# STM32MP25_CM33 register map
File version: 1.3
CPU: CM33 r0p1, little endian, MPU, FPU, vendor SysTick, 8 interrupt priority bits
Registers are 32-bit, read-write, reset 0x0 unless marked. A register's access mark holds for its fields unless they carry their own. Offsets are from the block's base; [hi:lo] are bit positions; {n}, {i} and the like mark numbered series; 'fields as' and 'values as' point back to an identical list.

## ETHSW (part 2 of 2) — ETHSW register block
Base 0x4C000000
Same registers: ETHSW_S 0x5C000000
{0x220040+2i} ETHSW_FES2_FRAMESIZE{i}R 16-bit reset 0x7FF (i=0..7) — ETHSW FES port 2 frame size {i} configuration register
  [10:0] FRAMESIZE — Max frame size
{0x2200E0+2i} ETHSW_FES2_FL_Q{i}_MINR 16-bit (i=0..7) — ETHSW FES port 2 minimum fill level queue {i} register
  [4:0] FL_QY_MIN — Minimum fill level for queue y
{0x2200F0+2i} ETHSW_FES2_FL_Q{i}_MAXR 16-bit (i=0..7) — ETHSW FES port 2 maximum fill level queue {i} register
  [4:0] FL_QY_MAX — Maximum fill level for queue y
0x800000 ETHSW_FES_IPC_IDR ro reset 0x4000 — ETHSW FES IP core identification register
  [31:8] DEV_ID — Device ID
    64=FES
0x800004 ETHSW_FES_CFG_IDR 16-bit ro reset 0x1 — ETHSW FES configuration ID register
  [15:0] CFG_ID — Configuration ID
0x800006 ETHSW_FES_REV_ID0R 16-bit ro reset 0xF2AF — ETHSW FES revision ID register 0
  [15:0] REV_ID0 — Configuration revision ID 0
0x800008 ETHSW_FES_REV_ID1R 16-bit ro reset 0x71CA — ETHSW FES revision ID register 1
  [15:0] REV_ID1 — Body revision ID, bit (15:0)
0x80000A ETHSW_FES_REV_ID2R 16-bit ro reset 0x57D — ETHSW FES revision ID register 2
  [15:0] REV_ID2 — Body revision ID, bit (31:16)
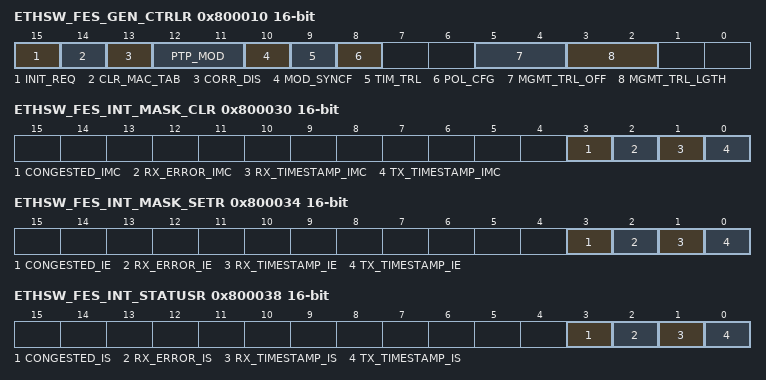
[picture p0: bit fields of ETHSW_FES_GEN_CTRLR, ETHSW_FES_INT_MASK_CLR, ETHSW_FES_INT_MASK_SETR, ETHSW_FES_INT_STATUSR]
0x800010 ETHSW_FES_GEN_CTRLR 16-bit — ETHSW FES general control register
  [15] INIT_REQ — Init Request
    0=Initialization release; 1=Initialization request
  [14] CLR_MAC_TAB — Clear Dynamic MAC address table
  [13] CORR_DIS — Correction Disable
    0=correctionFields of Store-and-forward PTPv2 event messages (Sync, Delay_Req, Pdelay_Req and Pdelay_Resp) are modified to include the time the frame spent inside the switch and for Sync frames optionally the link delay of the ingress port; 1=correctionFields of PTPv2 event messages are not modified by FES
  [12:11] PTP_MOD — PTP Mode
    0=PTP over UDP/IPv4; 2=PTP over Ethernet
  [10] MOD_SYNCF — Modify Sync frames
    0=Disabled; 1=Enabled
  [9] TIM_TRL — Time trailer
    0=Disabled; 1=Enabled
  [8] POL_CFG — Policer configuration
    0=Policing based on IPO; 1=Policing based on Static MAC Address Table
  [5:4] MGMT_TRL_OFF — Management Trailer Offset
    0=normal operation; 1=8-bit offset
  [3:2] MGMT_TRL_LGTH — Management Trailer Length
    0=8 bits; 1=16 bits
0x800012 ETHSW_FES_MT_CLEAR_MSKR 16-bit reset 0x7 — ETHSW FES dynamic MAC table clear mask register
  [2:0] MAC_TAB_CLRM — MAC Table Clear Mask
    0=Entries registered to this port are not cleared; 1=Entries registered to this port are cleared
0x800014 ETHSW_FES_MT_CLEAR_FIDR 16-bit — ETHSW FES dynamic MAC table clear FID register
  [5:0] FID — Filtering Identifier (FID)
0x800020 ETHSW_FES_ADDRESS_AGING_CFGR 16-bit reset 0x12 — ETHSW FES address aging configuration register
  [6:0] LIFE_TIME — Address Lifetime
    0=16s; 1=32s
0x800022 ETHSW_FES_AGING_BASE_TIMELR 16-bit reset 0xA11F — ETHSW FES aging base time low register
  [15:0] BASE_TIMEL — Aging base time value bits (15:0)
0x800024 ETHSW_FES_AGING_BASE_TIMEHR 16-bit reset 0x7 — ETHSW FES aging base time high register
  [7:0] BASE_TIMEH — Aging base time value bits (23:16)
0x800030 ETHSW_FES_INT_MASK_CLR 16-bit — ETHSW FES interrupt mask clear register
  [3] CONGESTED_IMC — Congested interrupt mask clear
  [2] RX_ERROR_IMC — RX error interrupt mask clear
  [1] RX_TIMESTAMP_IMC — RX timestamp interrupt mask clear
  [0] TX_TIMESTAMP_IMC — TX timestamp interrupt mask clear
0x800034 ETHSW_FES_INT_MASK_SETR 16-bit — ETHSW FES interrupt mask set register
  [3] CONGESTED_IE — Congested interrupt enable mask
  [2] RX_ERROR_IE — RX error interrupt enable mask
  [1] RX_TIMESTAMP_IE — RX timestamp interrupt enable mask
  [0] TX_TIMESTAMP_IE — TX timestamp interrupt enable mask
0x800038 ETHSW_FES_INT_STATUSR 16-bit — ETHSW FES interrupt status register
  [3] CONGESTED_IS — Congested interrupt status
  [2] RX_ERROR_IS — RX error interrupt status
  [1] RX_TIMESTAMP_IS — RX timestamp interrupt status
  [0] TX_TIMESTAMP_IS — TX timestamp interrupt status
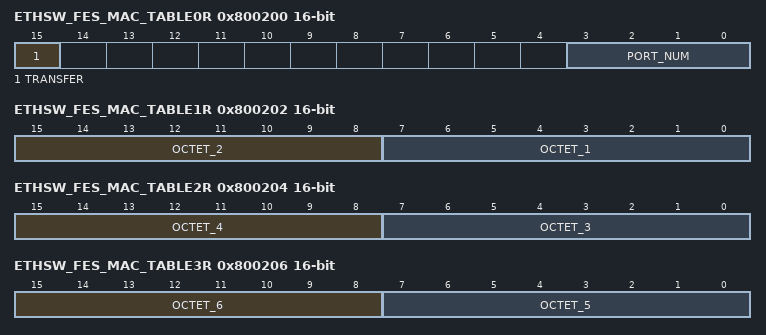
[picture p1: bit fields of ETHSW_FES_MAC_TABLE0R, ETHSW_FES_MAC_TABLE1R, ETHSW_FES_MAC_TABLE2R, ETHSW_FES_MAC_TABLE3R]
0x800200 ETHSW_FES_MAC_TABLE0R 16-bit — ETHSW FES dynamic MAC table read 0 register
  [15] TRANSFER
  [3:0] PORT_NUM ro — Port number
0x800202 ETHSW_FES_MAC_TABLE1R 16-bit ro — ETHSW FES dynamic MAC table read 1 register
  [15:8] OCTET_2 — Dynamic MAC Address Table Read: 2less thansup>ndless than/sup> octet
  [7:0] OCTET_1 — Dynamic MAC Address Table Read: 1less thansup>stless than/sup> octet
0x800204 ETHSW_FES_MAC_TABLE2R 16-bit ro — ETHSW FES dynamic MAC table read 2 register
  [15:8] OCTET_4 — Dynamic MAC Address Table Read: 4less thansup>thless than/sup> octet
  [7:0] OCTET_3 — Dynamic MAC Address Table Read: 3less thansup>rdless than/sup> octet
0x800206 ETHSW_FES_MAC_TABLE3R 16-bit ro — ETHSW FES dynamic MAC table read 3 register
  [15:8] OCTET_6 — Dynamic MAC Address Table Read: 6less thansup>thless than/sup> octet
  [7:0] OCTET_5 — Dynamic MAC Address Table Read: 5less thansup>thless than/sup> octet
0x800208 ETHSW_FES_MAC_TABLE4R 16-bit ro — ETHSW FES dynamic MAC table read 4 register
  [5:0] FID
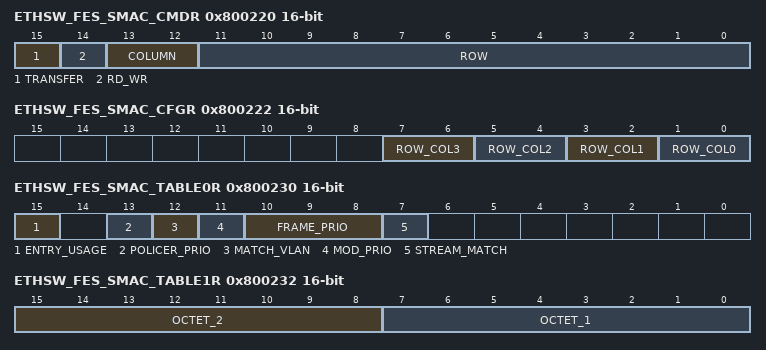
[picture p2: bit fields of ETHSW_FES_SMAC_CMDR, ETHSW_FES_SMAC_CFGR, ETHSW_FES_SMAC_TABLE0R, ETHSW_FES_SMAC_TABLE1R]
0x800220 ETHSW_FES_SMAC_CMDR 16-bit — ETHSW FES static MAC address table R/W command register
  [15] TRANSFER
  [14] RD_WR — Read / write
    0=Read values from Static MAC Table Entry to registers; 1=Write values from registers into Static MAC Table Entry
  [13:12] COLUMN
  [11:0] ROW
0x800222 ETHSW_FES_SMAC_CFGR 16-bit — ETHSW FES static MAC address table configuration register
  [7:6] ROW_COL3 — Row selection setting for column 3
  [5:4] ROW_COL2 — Row selection setting for column 2
  [3:2] ROW_COL1 — Row selection setting for column1
  [1:0] ROW_COL0 — Row selection setting for column 0
    0=XOR with VLAN disabled; 1=XOR with VLAN enabled
0x800230 ETHSW_FES_SMAC_TABLE0R 16-bit — ETHSW FES static MAC address table read/write 0 register
  [15] ENTRY_USAGE
    0=The entry is not used for altering Forward PortMask, Priority and Policer number for frames; 1=The entry is used for altering Forward PortMask of frames
  [13] POLICER_PRIO — Policer priority
    0=Normal Policer priority; 1=Low Policer priority, frames with lower policer priority use only the upper half of the token buckets
  [12] MATCH_VLAN
    0=Do not care about the VLAN of the frame; 1=Check that the value in VLAN field (ETHSW FES static MAC address table read/write 7 register (ETHSW_FES_SMAC_TABLE7R)) matches to VLAN of the frame
  [11] MOD_PRIO — Modify Priority
    0=Do not change frame priority; 1=Change the priority of the frame to the value in bits (10:8) of this register
  [10:8] FRAME_PRIO — Frame Priority
  [7] STREAM_MATCH — Stream_number source/destination match
    0=stream_number in this entry is used only for frames whose source address matches to the address in registers from ETHSW FES static MAC address table read/write 1 register (ETHSW_FES_SMAC_TABLE1R) to ETHSW FES static MAC address table read/write 3 register (ETHSW_FES_SMAC_TABLE3R); 1=stream_number in this entry is used only for frames whose destination address matches to the address in registers from ETHSW FES static MAC address table read/write 1 register (ETHSW_FES_SMAC_TABLE1R) to ETHSW FES static MAC address table read/write 3 register (ETHSW_FES_SMAC_TABLE3R)
0x800232 ETHSW_FES_SMAC_TABLE1R 16-bit — ETHSW FES static MAC address table read/write 1 register
  [15:8] OCTET_2 — Static MAC Address Table Read: 2less thansup>ndless than/sup> octet
  [7:0] OCTET_1 — Static MAC Address Table Read: 1less thansup>stless than/sup> octet
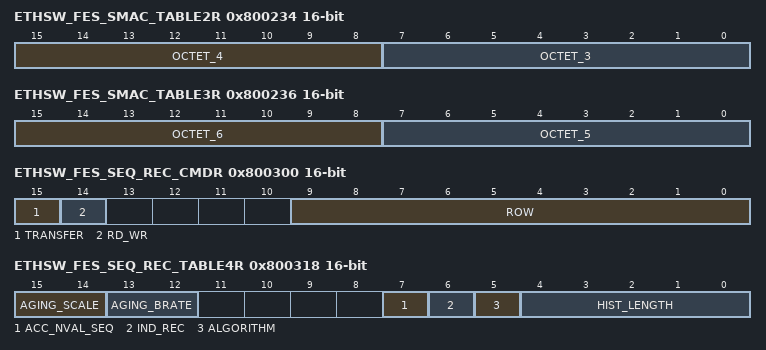
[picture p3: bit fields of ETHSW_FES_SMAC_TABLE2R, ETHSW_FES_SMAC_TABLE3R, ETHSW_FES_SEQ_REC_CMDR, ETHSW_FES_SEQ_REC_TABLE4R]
0x800234 ETHSW_FES_SMAC_TABLE2R 16-bit — ETHSW FES static MAC address table read/write 2 register
  [15:8] OCTET_4 — Static MAC Address Table Read: 4less thansup>thless than/sup> octet
  [7:0] OCTET_3 — Static MAC Address Table Read: 3less thansup>rdless than/sup> octet
0x800236 ETHSW_FES_SMAC_TABLE3R 16-bit — ETHSW FES static MAC address table read/write 3 register
  [15:8] OCTET_6 — Static MAC Address Table Read: 6less thansup>thless than/sup> octet
  [7:0] OCTET_5 — Static MAC Address Table Read: 5less thansup>thless than/sup> octet
0x800238 ETHSW_FES_SMAC_TABLE4R 16-bit — ETHSW FES static MAC address table read/write 4 register
  [2:0] FWD_PORT_MSK — Forward Port Mask
    0=Do not forward frames whose destination address matches to the port; 1=Forward frames whose destination address matches to the port
0x80023A ETHSW_FES_SMAC_TABLE5R 16-bit — ETHSW FES static MAC address table read/write 5 register
  [2:0] POLICER_PORTS — Policed Ports
    0=Keep the default policer for this input port; 1=Change policer mapping (to Policer Number in ETHSW FES static MAC address table read/write 6 register (ETHSW_FES_SMAC_TABLE6R)) for this input port
0x80023C ETHSW_FES_SMAC_TABLE6R 16-bit — ETHSW FES static MAC address table read/write 6 register
  [11:0] POLICER_NUM — Policer Number
0x80023E ETHSW_FES_SMAC_TABLE7R 16-bit — ETHSW FES static MAC address table read/write 7 register
  [11:0] VLAN
0x800300 ETHSW_FES_SEQ_REC_CMDR 16-bit — ETHSW FES sequence recovery table R/W command register
  [15] TRANSFER
  [14] RD_WR — Read / write
    0=Read value from Sequence Recovery Table row to ETHSW FES sequence recovery table read/write 4 register (ETHSW_FES_SEQ_REC_TABLE4R); 1=Write value from ETHSW FES sequence recovery table read/write 4 register (ETHSW_FES_SEQ_REC_TABLE4R) to Sequence Generation Table row
  [9:0] ROW
0x800318 ETHSW_FES_SEQ_REC_TABLE4R 16-bit — ETHSW FES sequence recovery table read/write 4 register
  [15:14] AGING_SCALE — Aging rate scale
  [13:12] AGING_BRATE — Aging basic rate
  [7] ACC_NVAL_SEQ — Accept non valid sequence
    0=Drop frames that have no valid sequence number; 1=Accept frames that have no valid sequence number
  [6] IND_REC — Individual recovery
    0=Frames discarded as duplicates do not cause the aging timer to be reset; 1=Frames discarded as duplicates cause the aging timer to be reset
  [5] ALGORITHM
    0=Vector Recovery Algorithm; 1=Match Recovery Algorithm
  [4:0] HIST_LENGTH — History Length - 1
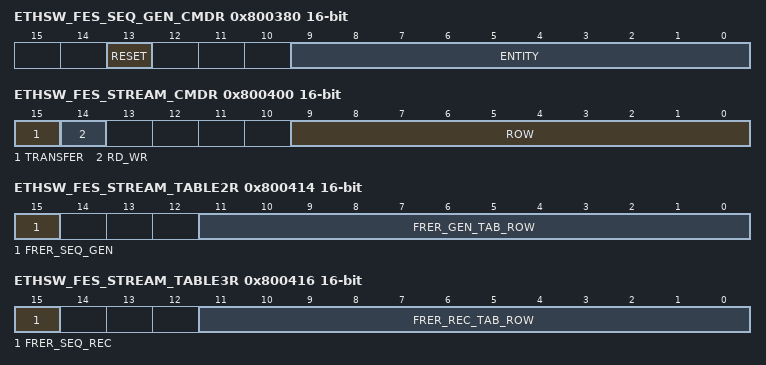
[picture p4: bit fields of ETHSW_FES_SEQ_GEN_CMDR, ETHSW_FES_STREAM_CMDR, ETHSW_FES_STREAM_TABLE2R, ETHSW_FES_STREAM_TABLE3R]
0x800380 ETHSW_FES_SEQ_GEN_CMDR 16-bit — ETHSW FES sequence generation command register
  [13] RESET
    0=Do nothing; 1=Reset sequence number
  [9:0] ENTITY
0x800400 ETHSW_FES_STREAM_CMDR 16-bit — ETHSW FES stream table R/W command register
  [15] TRANSFER
  [14] RD_WR — Read / write
    0=Read values from Stream Table row to registers from ETHSW FES stream table read/write 0 register (ETHSW_FES_STREAM_TABLE0R) to ETHSW FES stream table read/write 3 register (ETHSW_FES_STREAM_TABLE3R); 1=Write values from registers ETHSW FES stream table read/write 0 register (ETHSW_FES_STREAM_TABLE0R) to ETHSW FES stream table read/write 3 register (ETHSW_FES_STREAM_TABLE3R) into Stream Table row
  [9:0] ROW
0x800410 ETHSW_FES_STREAM_TABLE0R 16-bit — ETHSW FES stream table read/write 0 register
  [2:0] RMV_RTAG — Remove R-TAGging input port vector
    0=Keep R-TAGging; 1=Remove R-TAGging
0x800412 ETHSW_FES_STREAM_TABLE1R 16-bit — ETHSW FES stream table read/write 1 register
  [2:0] ADD_RTAG — Add R-TAGging output port vector
    0=Keep R-TAGging; 1=Add R-TAGging
0x800414 ETHSW_FES_STREAM_TABLE2R 16-bit — ETHSW FES stream table read/write 2 register
  [15] FRER_SEQ_GEN — FRER sequence generation enable
    0=Sequence generation functionality disabled for the stream; 1=Sequence generation functionality enabled, bits (11:0) of this register provide a pointer to Sequence generation table row (Sequence generation function entity)
  [11:0] FRER_GEN_TAB_ROW — FRER sequence generation table row
0x800416 ETHSW_FES_STREAM_TABLE3R 16-bit — ETHSW FES stream table read/write 3 register
  [15] FRER_SEQ_REC — FRER sequence recovery enable
    0=Sequence recovery functionality disabled for the stream; 1=Sequence recovery functionality enabled, bits (11:0) of this register provide a pointer to Sequence recovery table row (Sequence recovery function entity)
  [11:0] FRER_REC_TAB_ROW — FRER sequence recovery table row
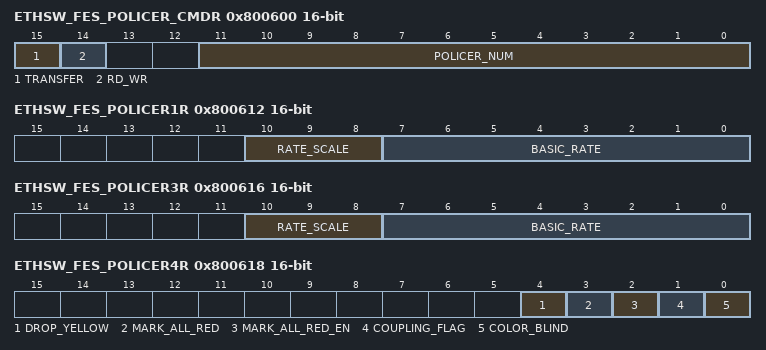
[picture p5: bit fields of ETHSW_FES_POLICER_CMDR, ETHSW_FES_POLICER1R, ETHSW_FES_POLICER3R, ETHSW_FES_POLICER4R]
0x800600 ETHSW_FES_POLICER_CMDR 16-bit — ETHSW FES policer read/write command register
  [15] TRANSFER
  [14] RD_WR — Read / write
    0=Read values from policer internal registers to registers ETHSW FES policer read/write 0 register (ETHSW_FES_POLICER0R) to ETHSW FES policer read/write 4 register (ETHSW_FES_POLICER4R); 1=Write values from registers ETHSW FES policer read/write 0 register (ETHSW_FES_POLICER0R) to ETHSW FES policer read/write 4 register (ETHSW_FES_POLICER4R) to policer internal registers
  [11:0] POLICER_NUM — Policer Number
0x800610 ETHSW_FES_POLICER0R 16-bit — ETHSW FES policer read/write 0 register
  [15:0] LIMIT
0x800612 ETHSW_FES_POLICER1R 16-bit — ETHSW FES policer read/write 1 register
  [10:8] RATE_SCALE — Rate Scale of Meter 0 (the meter for green)
  [7:0] BASIC_RATE — Basic Rate of Meter 0 (the meter for green)
0x800614 ETHSW_FES_POLICER2R 16-bit — ETHSW FES policer read/write 2 register
  [15:0] LIMIT
0x800616 ETHSW_FES_POLICER3R 16-bit — ETHSW FES policer read/write 3 register
  [10:8] RATE_SCALE — Rate Scale of Meter 1 (the meter for yellow / red)
  [7:0] BASIC_RATE — Basic Rate of Meter 1 (the meter for yellow / red)
0x800618 ETHSW_FES_POLICER4R 16-bit — ETHSW FES policer read/write 4 register
  [4] DROP_YELLOW — Drop on Yellow
    0=Disabled; 1=Enabled
  [3] MARK_ALL_RED — Mark all Frames Red
  [2] MARK_ALL_RED_EN — Mark all Frames Red Enable
    0=Disabled; 1=Enabled
  [1] COUPLING_FLAG
    0=No coupling between Meter 0 and Meter 1; 1=Tokens overflowing from the bucket of Meter 0 (green) are given to Meter 1 (yellow / red)
  [0] COLOR_BLIND
    0=Color Aware; 1=Color Blind
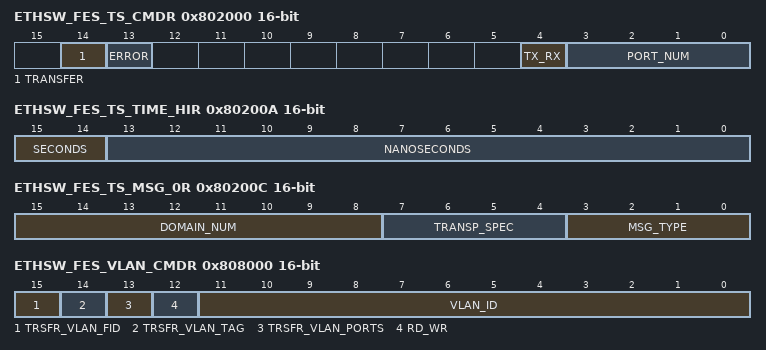
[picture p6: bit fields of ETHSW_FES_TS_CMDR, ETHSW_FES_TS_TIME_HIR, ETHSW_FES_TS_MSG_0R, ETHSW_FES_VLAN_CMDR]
0x802000 ETHSW_FES_TS_CMDR 16-bit — ETHSW FES timestamp command register
  [14] TRANSFER
  [13] ERROR ro
    0=Previous transfer command, initiated by writing 1 to the Transfer bit, was successful; 1=Previous transfer command failed because there was no stored timestamp information to fetch
  [4] TX_RX
    0=The next stored TX timestamp of the port is fetched when writing 1 to the transfer bit; 1=The next stored RX timestamp of the port is fetched when writing 1 to the transfer bit
  [3:0] PORT_NUM — Port Number
0x802008 ETHSW_FES_TS_TIME_LOR 16-bit ro — ETHSW FES timestamp time low register
  [15:0] NANOSECONDS — Nanoseconds, bits (15:0)
0x80200A ETHSW_FES_TS_TIME_HIR 16-bit ro — ETHSW FES timestamp time high register
  [15:14] SECONDS — Seconds, bits (0:1)
  [13:0] NANOSECONDS — Nanoseconds, bits (29:16)
0x80200C ETHSW_FES_TS_MSG_0R 16-bit ro — ETHSW FES timestamp PTP message 0 register
  [15:8] DOMAIN_NUM — Domain number
  [7:4] TRANSP_SPEC — Transport specific
  [3:0] MSG_TYPE — Message type
0x80200E ETHSW_FES_TS_MSG_1R 16-bit ro — ETHSW FES timestamp PTP message 1 register
  [15:0] SEQUENCE_ID
0x802010 ETHSW_FES_TS_RX_STATUSR 16-bit ro — ETHSW FES timestamp status port vector RX register
  [2:1] TS_STATUS_IN — Timestamp status input port vector
    0=There is no stored timestamp for this input port; 1=There is at least one stored timestamp for this input port
0x802012 ETHSW_FES_TS_TX_STATUSR 16-bit ro — ETHSW FES timestamp status port vector TX register
  [2:1] TS_STATUS_OUT — Timestamp status output port vector
    0=There is no stored timestamp for this output port; 1=There is at least one stored timestamp for this output port
0x808000 ETHSW_FES_VLAN_CMDR 16-bit — ETHSW FES VLAN command register
  [15] TRSFR_VLAN_FID — Transfer VLAN_FID
    0=Do not transfer data to/from VLAN_FID register; 1=Transfer data to/from (depending of read/write bit) VLAN_FID register
  [14] TRSFR_VLAN_TAG — Transfer VLAN_TAG
    0=Do not transfer data to/from VLAN_TAG register; 1=Transfer data to/from (depending of read/write bit) VLAN_TAG register
  [13] TRSFR_VLAN_PORTS — Transfer VLAN_PORTS
    0=Do not transfer data to/from VLAN_PORTS register; 1=Transfer data to/from (depending of read/write bit) VLAN_PORTS register
  [12] RD_WR — Read/Write
    0=Read settings; 1=Write settings
  [11:0] VLAN_ID
0x808008 ETHSW_FES_VLAN_PORTSR 16-bit — ETHSW FES port VLAN membership register
  [2:0] VLAN_MEMBER — VLAN membership
    0=The port is not a member of this VLAN; 1=The port is a member of this VLAN
0x80800A ETHSW_FES_VLAN_TAGR 16-bit — ETHSW FES port VLAN tagging register
  [2:0] VLAN_TAG — VLAN tagging
    0=Tagging enabled for the port, if enabled in ETHSW FES port x port VLAN configuration register 1 (ETHSW_FESx_VLAN1R) (x = 0 to 2), bit TGD_UTGD; 1=Tagging disabled for the port
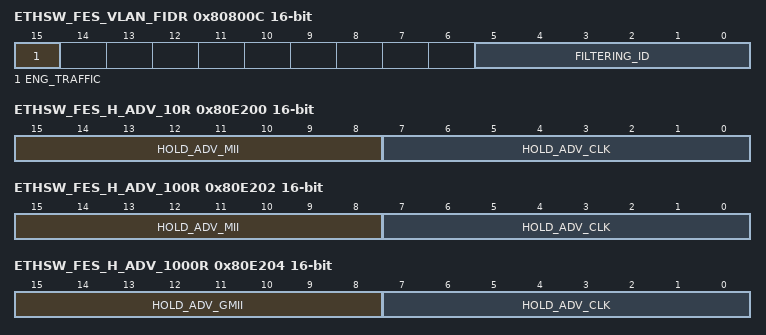
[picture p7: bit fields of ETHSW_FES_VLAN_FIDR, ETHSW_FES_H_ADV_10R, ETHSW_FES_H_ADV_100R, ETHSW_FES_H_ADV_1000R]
0x80800C ETHSW_FES_VLAN_FIDR 16-bit — ETHSW FES Filtering ID register
  [15] ENG_TRAFFIC — Engineered Traffic
    0=Engineered traffic disabled, address learning is enabled and the traffic destined to unlearned/unconfigured unicast or multicast/broadcast destinations is sent to all ports (if allowed); 1=Engineered traffic enabled, address learning is disabled and the traffic destined to unconfigured unicast or multicast/broadcast destinations is dropped
  [5:0] FILTERING_ID
    0=FID 0; 1=FID 1
0x80E000 ETHSW_FES_PORT_HIGHR 16-bit ro reset 0x2 — ETHSW FES FES_PORT_HIGH generic register
  [3:0] FES_PORT_HIGH — The value of generic FES_PORT_HIGH
0x80E002 ETHSW_FES_COUNTERSR 16-bit ro reset 0x3 — ETHSW FES COUNTERS generic register
  [2:0] COUNTERS — The value of generic COUNTERS
0x80E004 ETHSW_FES_CT_PORTSR 16-bit ro reset 0x6 — ETHSW FES CT_PORTS generic register
  [11:0] CT_PORTS — The value of generic CT_PORTS
0x80E006 ETHSW_FES_TS_PORTSR 16-bit ro reset 0x6 — ETHSW FES TS_PORTS generic register
  [11:0] TS_PORTS — The value of generic TS_PORTS
0x80E008 ETHSW_FES_SMAC_TABLE_ROWSR 16-bit ro reset 0xA — ETHSW FES SMAC_TABLE_ROWS generic register
  [3:0] SMAC_TABLE_ROWS — The value of generic SMAC_TABLE_ROWS
0x80E00A ETHSW_FES_POLICINGR 16-bit ro reset 0x3 — ETHSW FES POLICING generic register
  [1:0] POLICING — The value of generic POLICING
    0=No policer function; 1=Policer via IPO; 2=Policer via SMAC; 3=Policing via both IPO/SMAC selectable by software
0x80E00C ETHSW_FES_POLICERSR 16-bit ro reset 0x7 — ETHSW FES POLICERS generic register
  [3:0] POLICERS — The value of generic POLICERS
0x80E00E ETHSW_FES_QUEUESR 16-bit ro reset 0x8 — ETHSW FES QUEUES generic register
  [3:0] QUEUES — The value of generic QUEUES
0x80E010 ETHSW_FES_BUFFER_SIZER 16-bit ro reset 0x1 — ETHSW FES BUFFER_SIZE generic register
  [0] BUFFER_SIZE — The value of generic BUFFER_SIZE
    0=Normal; 1=Double
0x80E012 ETHSW_FES_SHAPERSR 16-bit ro reset 0x1 — ETHSW FES SHAPERS generic register
  [0] SHAPERS — The value of generic SHAPERS
    0=Disabled; 1=Enabled
0x80E014 ETHSW_FES_GIGABITR 16-bit ro reset 0x1 — ETHSW FES GIGABIT generic register
  [0] GIGABIT — The value of generic GIGABIT
    0=all ports 10/100Mbps only; 1=all ports 10/100/1000Mbps
0x80E016 ETHSW_FES_HSR_PORTSR 16-bit ro — ETHSW FES HSR_PORTS generic register
  [7:0] HSR_PORTS — The value of generic HSR_PORTS
    0=Disabled; 1=Enabled
0x80E018 ETHSW_FES_PRP_PORTSR 16-bit ro — ETHSW FES PRP_PORTS generic register
  [7:0] PRP_PORTS — The value of generic PRP_PORTS
    0=Disabled; 1=Enabled
0x80E01A ETHSW_FES_SCHEDULED_PORTSR 16-bit ro reset 0x7 — ETHSW FES SCHEDULED_PORTS generic register
  [11:0] SCHEDULED_PORTS — The value of generic SCHEDULED_PORTS
    0=Disabled; 1=Enabled
0x80E01C ETHSW_PREEMPTABLE_PORTR 16-bit ro reset 0x6 — ETHSW FES PREEMPTABLE_PORT generic register
  [11:0] PREEMPTABLE_PORT — The value of generic PREEMPTABLE_PORT
    0=Disabled; 1=Enabled
0x80E01E ETHSW_FES_MACSECR 16-bit ro — ETHSW FES MACSEC generic register
  [11:0] MACSEC — The value of generic MACSEC
    0=Disabled; 1=Enabled
0x80E020 ETHSW_FES_MACSEC_CIPHERR 16-bit ro — ETHSW FES MACSEC_CIPHER generic register
  [2:0] MACSEC_CIPHER — The value of generic MACSEC_CIPHER
    1=AES-GCM-128
0x80E022 ETHSW_FES_MGMT_PORTSR 16-bit ro reset 0x1 — ETHSW FES MGMT_PORTS generic register
  [11:0] MGMT_PORTS — The value of generic MGMT_PORTS
    0=Disabled; 1=Enabled
0x80E024 ETHSW_FES_FRER_PORTSR 16-bit ro reset 0x7 — ETHSW FES FRER_PORTS generic register
  [7:0] FRER_PORTS — The value of generic FRER_PORTS
    0=Disabled; 1=Enabled
0x80E026 ETHSW_FES_FRER_ENTRIESR 16-bit ro reset 0xA — ETHSW FES FRER_ENTRIES generic register
  [3:0] FRER_ENTRIES — The value of generic FRER_ENTRIES
    2=1024 entries
0x80E028 ETHSW_FES_FRER_STREAMSR 16-bit ro reset 0x7 — ETHSW FES FRER_STREAMS generic register
  [3:0] FRER_STREAMS — The value of generic FRER_STREAMS
    2=1024 streams
0x80E02A ETHSW_FES_FIDSR 16-bit ro reset 0x6 — ETHSW FES FIDS generic register
  [5:0] FIDS — The value of generic FIDS
    0=Feature does not exist
0x80E02C ETHSW_FES_DMA_PORTSR 16-bit ro — ETHSW FES DMA_PORTS generic register
  [11:0] DMA_PORTS — The value of generic DMA_PORTS
    0=Disabled; 1=Enabled
0x80E02E ETHSW_FES_DMA_TX_DESC_RINGR 16-bit ro reset 0x1 — ETHSW FES DMA_TX_DESC_RING generic register
  [3:0] DMA_TX_DESC_RING — The value of generic DMA_TX_DESC_RING
0x80E030 ETHSW_FES_DMA_RX_DESC_RINGR 16-bit ro reset 0x1 — ETHSW FES DMA_RX_DESC_RING generic register
  [3:0] DMA_RX_DESC_RING — The value of generic DMA_RX_DESC_RING
0x80E032 ETHSW_FES_PSFPR 16-bit ro — ETHSW FES PSFP generic register
  [0] PSFP — The value of generic PSFP
0x80E034 ETHSW_FES_PSFP_STREAMSR 16-bit ro reset 0x7 — ETHSW FES PSFP_STREAMS generic register
  [3:0] PSFP_STREAMS — The value of generic PSFP_STREAMS
    2=1024 streams
0x80E100 ETHSW_FES_CFG_CLK_FREQR 16-bit ro reset 0xC8 — ETHSW FES CFG_CLK_FREQ register
  [7:0] CFG_CLK_FREQ — The value of generic CFG_CLK_FREQ
0x80E110 ETHSW_FES_DEBUG_INR 16-bit ro — ETHSW FES DEBUG_IN register
  [0] DEBUG_IN — The value of generic DEBUG_IN
0x80E200 ETHSW_FES_H_ADV_10R 16-bit ro — ETHSW FES hold advance 10M register
  [15:8] HOLD_ADV_MII — holdadvance_mii_cycles value
  [7:0] HOLD_ADV_CLK — holdadvance_clk_cycles value
0x80E202 ETHSW_FES_H_ADV_100R 16-bit ro — ETHSW FES hold advance 100M register
  fields as ETHSW_FES_H_ADV_10R
0x80E204 ETHSW_FES_H_ADV_1000R 16-bit ro — ETHSW FES hold advance 1000M register
  [15:8] HOLD_ADV_GMII — holdadvance_gmii_cycles value
  [7:0] HOLD_ADV_CLK — holdadvance_clk_cycles value
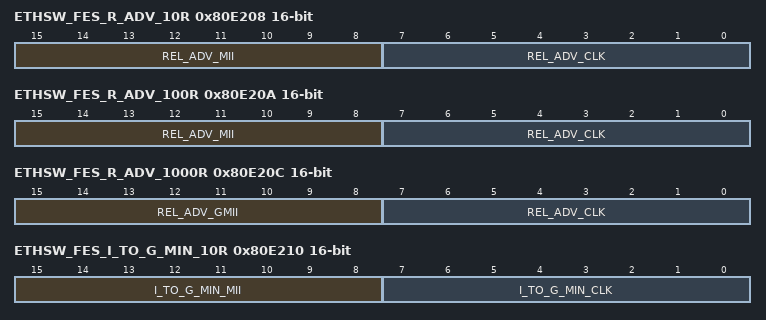
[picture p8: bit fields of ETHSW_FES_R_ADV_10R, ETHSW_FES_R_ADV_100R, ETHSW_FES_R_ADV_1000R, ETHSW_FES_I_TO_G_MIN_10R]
0x80E208 ETHSW_FES_R_ADV_10R 16-bit ro — ETHSW FES release advance 10M register
  [15:8] REL_ADV_MII — releaseadvance_mii_cycles value
  [7:0] REL_ADV_CLK — releaseadvance_clk_cycles value
0x80E20A ETHSW_FES_R_ADV_100R 16-bit ro — ETHSW FES release advance 100M register
  fields as ETHSW_FES_R_ADV_10R
0x80E20C ETHSW_FES_R_ADV_1000R 16-bit ro — ETHSW FES release advance 1000M register
  [15:8] REL_ADV_GMII — releaseadvance_gmii_cycles value
  [7:0] REL_ADV_CLK — releaseadvance_clk_cycles value
0x80E210 ETHSW_FES_I_TO_G_MIN_10R 16-bit ro — ETHSW FES minimum input to gate delay 10M register
  [15:8] I_TO_G_MIN_MII — inputtogate_mii_cycles value
  [7:0] I_TO_G_MIN_CLK — inputtogate_clk_cycles value
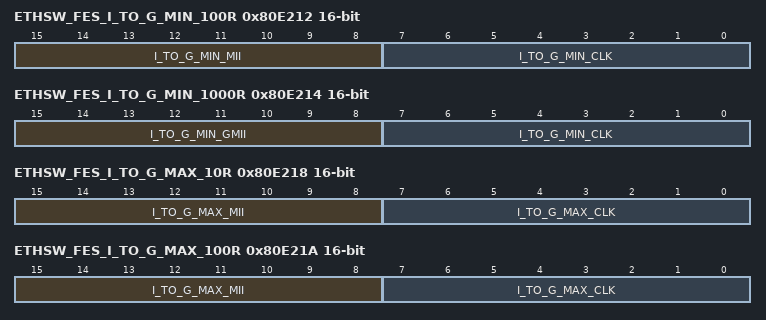
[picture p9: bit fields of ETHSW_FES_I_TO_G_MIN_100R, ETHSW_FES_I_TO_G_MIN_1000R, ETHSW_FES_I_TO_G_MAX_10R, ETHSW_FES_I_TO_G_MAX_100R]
0x80E212 ETHSW_FES_I_TO_G_MIN_100R 16-bit ro — ETHSW FES minimum input to gate delay 100M register
  fields as ETHSW_FES_I_TO_G_MIN_10R
0x80E214 ETHSW_FES_I_TO_G_MIN_1000R 16-bit ro — ETHSW FES minimum input to gate delay 1000M register
  [15:8] I_TO_G_MIN_GMII — inputtogate_gmii_cycles value
  [7:0] I_TO_G_MIN_CLK — inputtogate_clk_cycles value
0x80E218 ETHSW_FES_I_TO_G_MAX_10R 16-bit ro — ETHSW FES maximum input to gate delay 10M register
  [15:8] I_TO_G_MAX_MII — inputtogate_mii_cycles value
  [7:0] I_TO_G_MAX_CLK — inputtogate_clk_cycles value
0x80E21A ETHSW_FES_I_TO_G_MAX_100R 16-bit ro — ETHSW FES maximum input to gate delay 100M register
  fields as ETHSW_FES_I_TO_G_MAX_10R
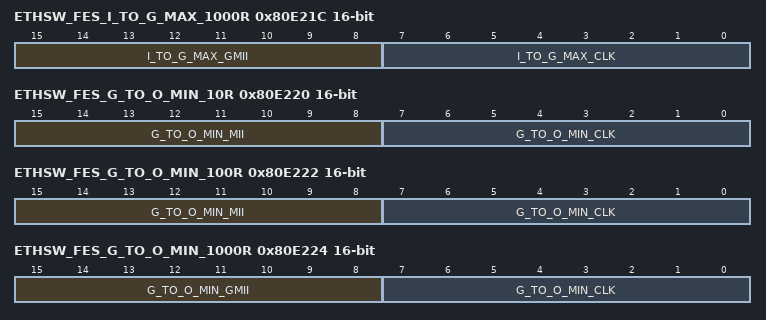
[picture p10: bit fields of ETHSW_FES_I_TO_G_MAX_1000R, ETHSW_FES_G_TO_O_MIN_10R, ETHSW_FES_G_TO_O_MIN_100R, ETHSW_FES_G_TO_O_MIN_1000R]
0x80E21C ETHSW_FES_I_TO_G_MAX_1000R 16-bit ro — ETHSW FES maximum input to gate delay 1000M register
  [15:8] I_TO_G_MAX_GMII — inputtogate_gmii_cycles value
  [7:0] I_TO_G_MAX_CLK — inputtogate_clk_cycles value
0x80E220 ETHSW_FES_G_TO_O_MIN_10R 16-bit ro — ETHSW FES minimum gate to output delay 10M register
  [15:8] G_TO_O_MIN_MII — gatetooutput_mii_cycles value
  [7:0] G_TO_O_MIN_CLK — gatetooutput_clk_cycles value
0x80E222 ETHSW_FES_G_TO_O_MIN_100R 16-bit ro — ETHSW FES minimum gate to output delay 100M register
  fields as ETHSW_FES_G_TO_O_MIN_10R
0x80E224 ETHSW_FES_G_TO_O_MIN_1000R 16-bit ro — ETHSW FES minimum gate to output delay 1000M register
  [15:8] G_TO_O_MIN_GMII — gatetooutput_gmii_cycles value
  [7:0] G_TO_O_MIN_CLK — gatetooutput_clk_cycles value
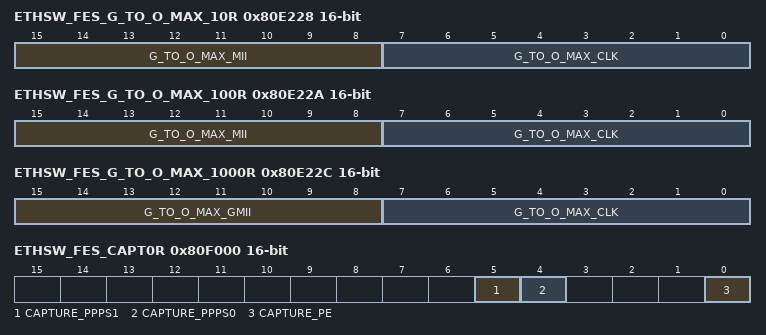
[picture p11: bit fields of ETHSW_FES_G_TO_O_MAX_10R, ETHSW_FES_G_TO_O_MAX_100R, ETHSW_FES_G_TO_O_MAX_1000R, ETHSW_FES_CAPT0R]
0x80E228 ETHSW_FES_G_TO_O_MAX_10R 16-bit ro — ETHSW FES maximum gate to output delay 10M register
  [15:8] G_TO_O_MAX_MII — gatetooutput_mii_cycles value
  [7:0] G_TO_O_MAX_CLK — gatetooutput_clk_cycles value
0x80E22A ETHSW_FES_G_TO_O_MAX_100R 16-bit ro — ETHSW FES maximum gate to output delay 100M register
  fields as ETHSW_FES_G_TO_O_MAX_10R
0x80E22C ETHSW_FES_G_TO_O_MAX_1000R 16-bit ro — ETHSW FES maximum gate to output delay 1000M register
  [15:8] G_TO_O_MAX_GMII — gatetooutput_gmii_cycles value
  [7:0] G_TO_O_MAX_CLK — gatetooutput_clk_cycles value
0x80F000 ETHSW_FES_CAPT0R 16-bit ro — ETHSW FES capture status 0 register
  [5] CAPTURE_PPPS1, [4] CAPTURE_PPPS0, [0] CAPTURE_PE
0x80F002 ETHSW_FES_CAPT1R 16-bit — ETHSW FES capture control 1 register
  [11:0] ENTITY
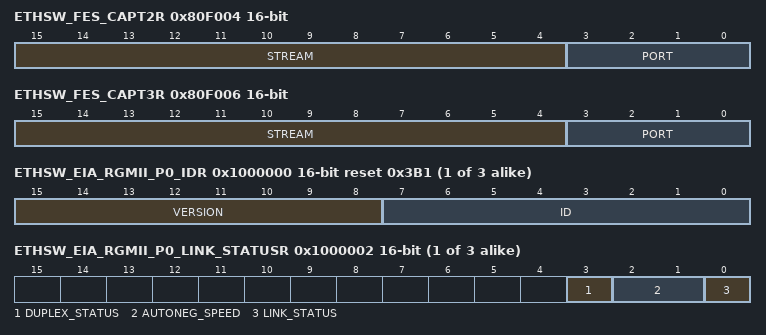
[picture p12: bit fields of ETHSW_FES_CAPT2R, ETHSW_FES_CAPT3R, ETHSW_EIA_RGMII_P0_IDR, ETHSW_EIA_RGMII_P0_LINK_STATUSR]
0x80F004 ETHSW_FES_CAPT2R 16-bit — ETHSW FES capture control 2 register
  [15:4] STREAM, [3:0] PORT
0x80F006 ETHSW_FES_CAPT3R 16-bit — ETHSW FES capture control 3 register
  [15:4] STREAM, [3:0] PORT
0x80F200 ETHSW_FES_SEQ_REC_TOUT_LR 16-bit ro — ETHSW FES sequence recovery timeouts low register
  [15:0] COUNTER — Counter value, bits (15:0)
0x80F202 ETHSW_FES_SEQ_REC_TOUT_HR 16-bit ro — ETHSW FES sequence recovery timeouts high register
  [15:0] COUNTER — Counter value, bits (31:16)
0x80F204 ETHSW_FES_VECT_JUMP_LR 16-bit ro — ETHSW FES vector recovery jump ahead low register
  [15:0] COUNTER — Counter value, bits (15:0)
0x80F206 ETHSW_FES_VECT_JUMP_HR 16-bit ro — ETHSW FES vector recovery jump ahead high register
  [15:0] COUNTER — Counter value, bits (31:16)
0x80F208 ETHSW_FES_SEQ_REC_OOO_LR 16-bit ro — ETHSW FES vector recovery out of order frames low register
  [15:0] COUNTER — Counter value, bits (15:0)
0x80F20A ETHSW_FES_SEQ_REC_OOO_HR 16-bit ro — ETHSW FES vector recovery out of order frames high register
  [15:0] COUNTER — Counter value, bits (31:16)
0x80F300 ETHSW_FES_FRAMES_IN_LR 16-bit ro — ETHSW FES input frames low register
  [15:0] COUNTER — Counter value, bits (15:0)
0x80F302 ETHSW_FES_FRAMES_IN_HR 16-bit ro — ETHSW FES input frames high register
  [15:0] COUNTER — Counter value, bits (31:16)
0x80F304 ETHSW_FES_FRAMES_OUT_LR 16-bit ro — ETHSW FES output frames low register
  [15:0] COUNTER — Counter value, bits (15:0)
0x80F306 ETHSW_FES_FRAMES_OUT_HR 16-bit ro — ETHSW FES output frames high register
  [15:0] COUNTER — Counter value, bits (31:16)
0x80F308 ETHSW_FES_SEQ_REC_OOO2_LR 16-bit ro — ETHSW FES vector recovery out of order frames low register
  [15:0] COUNTER — Counter value, bits (15:0)
0x80F30A ETHSW_FES_SEQ_REC_OOO2_HR 16-bit ro — ETHSW FES vector recovery out of order frames high register
  [15:0] COUNTER — Counter value, bits (31:16)
0x80F30C ETHSW_FES_VECT_ROG_LR 16-bit ro — ETHSW FES vector recovery rogue frames low register
  [15:0] COUNTER — Counter value, bits (15:0)
0x80F30E ETHSW_FES_VECT_ROG_HR 16-bit ro — ETHSW FES vector recovery rogue frames high register
  [15:0] COUNTER — Counter value, bits (31:16)
0x80F310 ETHSW_FES_SEQ_REC_TAGLESS_LR 16-bit ro — ETHSW FES sequence recovery tagless frames low register
  [15:0] COUNTER — Counter value, bits (15:0)
0x80F312 ETHSW_FES_SEQ_REC_TAGLESS_HR 16-bit ro — ETHSW FES sequence recovery tagless frames high register
  [15:0] COUNTER — Counter value, bits (31:16)
0x80F314 ETHSW_FES_SEQ_REC_SB_LR 16-bit ro — ETHSW FES sequence recovery frames seen before low register
  [15:0] COUNTER — Counter value, bits (15:0)
0x80F316 ETHSW_FES_SEQ_REC_SB_HR 16-bit ro — ETHSW FES sequence recovery frames seen before high register
  [15:0] COUNTER — Counter value, bits (31:16)
{0x1000000+0x200*i} ETHSW_EIA_RGMII_P{i}_IDR 16-bit ro reset 0x3B1 (i=0..2) — ETHSW EIA port {i} RGMII adapter ID register
  [15:8] VERSION
  [7:0] ID — Device ID
    177=RGMII adapter
{0x1000002+0x200*i} ETHSW_EIA_RGMII_P{i}_LINK_STATUSR 16-bit ro (i=0..2) — ETHSW EIA port {i} RGMII adapter link status register
  [3] DUPLEX_STATUS
    0=half-duplex; 1=full duplex
  [2:1] AUTONEG_SPEED
    0=Unknown; 1=1000 Mbps; 2=100 Mbps; 3=10 Mbps
  [0] LINK_STATUS
    0=link down
{0x1000020+0x200*i} ETHSW_EIA_RGMII_P{i}_RX_DELAYR 16-bit ro (i=0..2) — ETHSW EIA port {i} RGMII adapter RX delay register
  [15:0] RX_DELAY
{0x1000022+0x200*i} ETHSW_EIA_RGMII_P{i}_TX_DELAYR 16-bit ro (i=0..2) — ETHSW EIA port {i} RGMII adapter TX delay register
  [15:0] TX_DELAY
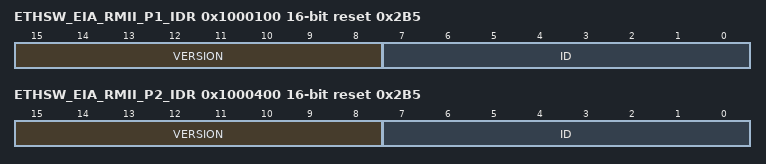
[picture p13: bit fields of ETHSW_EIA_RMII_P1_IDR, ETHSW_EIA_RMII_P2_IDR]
0x1000100 ETHSW_EIA_RMII_P1_IDR 16-bit ro reset 0x2B5 — ETHSW EIA port 1 RMII adapter ID register [alternate]
  [15:8] VERSION
  [7:0] ID — Device ID
    177=RGMII adapter
0x1000202 ETHSW_EIA_RMII_P1_LINK_STATUSR 16-bit (alternate view of ETHSW_EIA_RGMII_P1_LINK_STATUSR) — ETHSW EIA port 1 RMII adapter link status register [alternate]
  [0] LINK_STATUS
    0=link down; 1=link up
0x1000320 ETHSW_EIA_RMII_P1_RX_DELAYR 16-bit ro — ETHSW EIA port 1 RMII adapter RX delay register [alternate]
  [15:0] RX_DELAY
0x1000322 ETHSW_EIA_RMII_P1_TX_DELAYR 16-bit ro — ETHSW EIA port 1 RMII adapter TX delay register [alternate]
  [15:0] TX_DELAY
0x1000400 ETHSW_EIA_RMII_P2_IDR 16-bit ro reset 0x2B5 (alternate view of ETHSW_EIA_RGMII_P2_IDR) — ETHSW EIA port 2 RMII adapter ID register [alternate]
  [15:8] VERSION
  [7:0] ID — Device ID
    177=RGMII adapter
0x1000402 ETHSW_EIA_RMII_P2_LINK_STATUSR 16-bit (alternate view of ETHSW_EIA_RGMII_P2_LINK_STATUSR) — ETHSW EIA port 2 RMII adapter link status register [alternate]
  [0] LINK_STATUS
    0=link down; 1=link up
0x1000420 ETHSW_EIA_RMII_P2_RX_DELAYR 16-bit ro (alternate view of ETHSW_EIA_RGMII_P2_RX_DELAYR) — ETHSW EIA port 2 RMII adapter RX delay register [alternate]
  [15:0] RX_DELAY
0x1000422 ETHSW_EIA_RMII_P2_TX_DELAYR 16-bit ro (alternate view of ETHSW_EIA_RGMII_P2_TX_DELAYR) — ETHSW EIA port 2 RMII adapter TX delay register [alternate]
  [15:0] TX_DELAY
